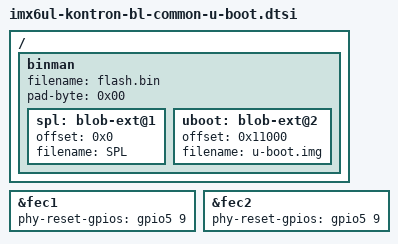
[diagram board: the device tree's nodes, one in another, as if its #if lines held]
// SPDX-License-Identifier: GPL-2.0 OR MIT
/*
 * Copyright (C) 2017 exceet electronics GmbH
 * Copyright (C) 2018 Kontron Electronics GmbH
 */

#if defined(CONFIG_FIT)

/ {
	binman: binman {
		filename = "flash.bin";
		pad-byte = <0x00>;

		spl: blob-ext@1 {
			offset = <0x0>;
			filename = "SPL";
		};

		uboot: blob-ext@2 {
			offset = <0x11000>;
			filename = "u-boot.img";
		};
	};
};

#endif /* CONFIG_FIT */

/*
 * To make the PHYs work, we need to set the reset pin once. Afterwards
 * in Linux we can't assign the shared reset GPIO to the PHYs, as this
 * would cause Linux to reset both PHYs every time one of them gets
 * reinitialized.
 */

&fec1 {
	pinctrl-names = "default";
	phy-reset-gpios = <&gpio5 9 GPIO_ACTIVE_HIGH>;
};

&fec2 {
	phy-reset-gpios = <&gpio5 9 GPIO_ACTIVE_HIGH>;
};
